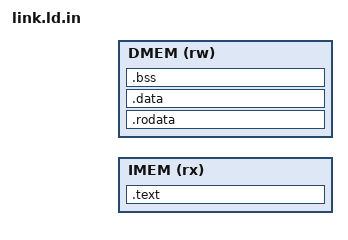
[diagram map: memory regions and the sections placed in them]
/* Generated by compile_tool/ldscript.py from the machine's own MemoryLayout.
 * Do not edit this copy — edit compile_tool/template/link.ld.in and rebuild,
 * or the script and the hardware stop agreeing. */

OUTPUT_ARCH(riscv)
ENTRY(_start)

MEMORY
{
  IMEM (rx) : ORIGIN = @IMEM_BASE@, LENGTH = @IMEM_BYTES@
  DMEM (rw) : ORIGIN = @DMEM_BASE@, LENGTH = @DATA_BYTES@
}

/* The I/O words, just above the allocatable end of the data region. The
 * harness watches these addresses on the store port; the memory behind them
 * is never read. */
@MMIO_SYMBOLS@
__stack_top = @STACK_TOP@;

SECTIONS
{
  /* ---- instruction memory: instructions and nothing else ---------------- */
  .text : ALIGN(4)
  {
    KEEP(*(.text.start))                      /* crt0 first — address 0 is the reset vector */
    *(.text .text.* .gnu.linkonce.t.*)
    . = ALIGN(4);
  } > IMEM

  /* ---- data memory: everything a load can reach ------------------------- */
  .rodata : ALIGN(4)
  {
    *(.rodata .rodata.* .gnu.linkonce.r.*)
    *(.srodata .srodata.*)
    . = ALIGN(4);
  } > DMEM

  .data : ALIGN(4)
  {
    *(.data .data.* .gnu.linkonce.d.*)
    . = ALIGN(4);
    __global_pointer$ = . + 0x800;            /* small-data addressing anchor */
    *(.sdata .sdata.* .gnu.linkonce.s.*)
    . = ALIGN(4);
  } > DMEM

  .bss (NOLOAD) : ALIGN(4)
  {
    __bss_start = .;
    *(.sbss .sbss.* .scommon)
    *(.bss .bss.* .gnu.linkonce.b.*)
    *(COMMON)
    . = ALIGN(4);
    __bss_end = .;
  } > DMEM

  /* .bss needs no zeroing code: the image is a zeroed buffer and a NOBITS
   * section contributes zeros to it (image.py), which is what memgen does. */

  /DISCARD/ :
  {
    *(.comment)
    *(.note .note.*)
    *(.riscv.attributes)
    *(.eh_frame .eh_frame_hdr)
  }
}
